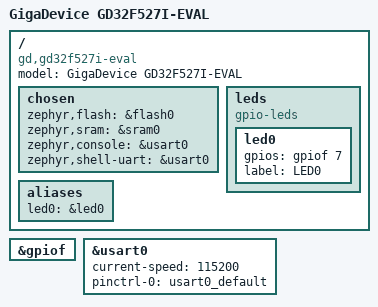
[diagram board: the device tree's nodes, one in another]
/*
 * Copyright (c) 2025, GigaDevice Semiconductor Inc.
 * SPDX-License-Identifier: Apache-2.0
 */

/dts-v1/;

#include <gd/gd32f527/gd32f527is.dtsi>
#include "gd32f527i_eval-pinctrl.dtsi"

/ {
	model = "GigaDevice GD32F527I-EVAL";
	compatible = "gd,gd32f527i-eval";

	chosen {
		zephyr,flash = &flash0;
		zephyr,sram = &sram0;
		zephyr,console = &usart0;
		zephyr,shell-uart = &usart0;
	};

	leds {
		compatible = "gpio-leds";
		led0: led0 {
			gpios = <&gpiof 7 GPIO_ACTIVE_HIGH>;
			label = "LED0";
		};
	};

	aliases {
		led0 = &led0;
	};
};

&gpiof {
	status = "okay";
};

&usart0 {
	status = "okay";
	current-speed = <115200>;
	pinctrl-0 = <&usart0_default>;
	pinctrl-names = "default";
};
